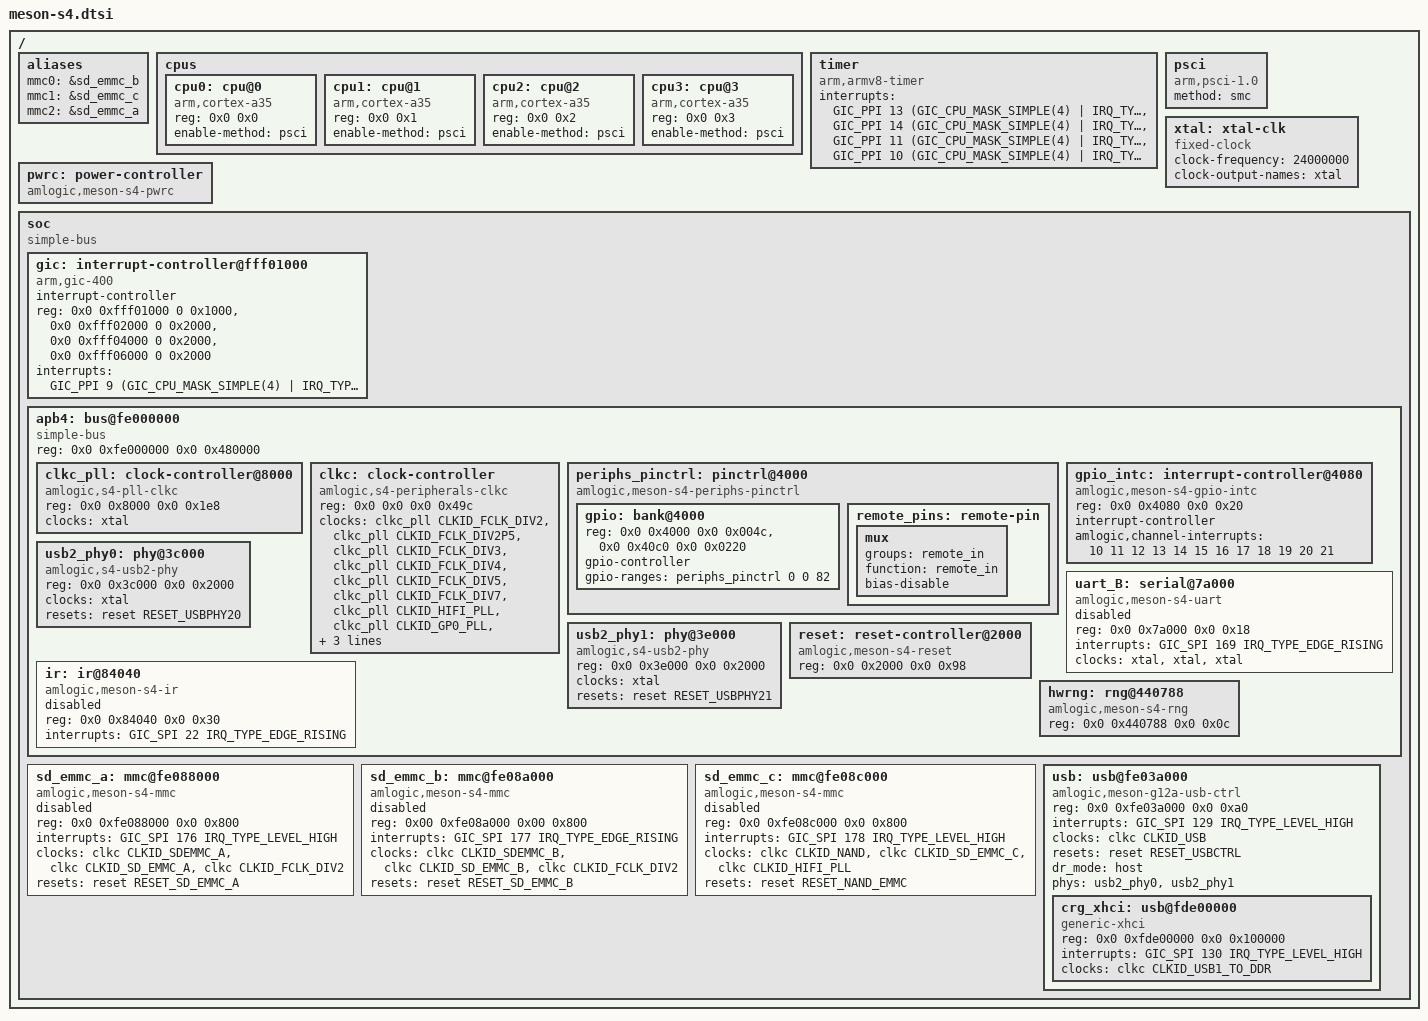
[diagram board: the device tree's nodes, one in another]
// SPDX-License-Identifier: (GPL-2.0+ OR MIT)
/*
 * Copyright (c) 2021 Amlogic, Inc. All rights reserved.
 */
 
#include <dt-bindings/clock/amlogic,s4-peripherals-clkc.h>
#include <dt-bindings/clock/amlogic,s4-pll-clkc.h>
#include <dt-bindings/interrupt-controller/irq.h>
#include <dt-bindings/interrupt-controller/arm-gic.h>
#include <dt-bindings/gpio/gpio.h>
#include <dt-bindings/reset/amlogic,meson-s4-reset.h>

/ {
	
	aliases {
        mmc0 = &sd_emmc_b; /* SD card */
        mmc1 = &sd_emmc_c; /* eMMC */
        mmc2 = &sd_emmc_a; /* SDIO */
    };
	
	cpus {
		#address-cells = <2>;
		#size-cells = <0>;

		cpu0: cpu@0 {
			device_type = "cpu";
			compatible = "arm,cortex-a35";
			reg = <0x0 0x0>;
			enable-method = "psci";
		};

		cpu1: cpu@1 {
			device_type = "cpu";
			compatible = "arm,cortex-a35";
			reg = <0x0 0x1>;
			enable-method = "psci";
		};

		cpu2: cpu@2 {
			device_type = "cpu";
			compatible = "arm,cortex-a35";
			reg = <0x0 0x2>;
			enable-method = "psci";
		};

		cpu3: cpu@3 {
			device_type = "cpu";
			compatible = "arm,cortex-a35";
			reg = <0x0 0x3>;
			enable-method = "psci";
		};
	};

	timer {
		compatible = "arm,armv8-timer";
		interrupts = <GIC_PPI 13 (GIC_CPU_MASK_SIMPLE(4) | IRQ_TYPE_LEVEL_LOW)>,
			     <GIC_PPI 14 (GIC_CPU_MASK_SIMPLE(4) | IRQ_TYPE_LEVEL_LOW)>,
			     <GIC_PPI 11 (GIC_CPU_MASK_SIMPLE(4) | IRQ_TYPE_LEVEL_LOW)>,
			     <GIC_PPI 10 (GIC_CPU_MASK_SIMPLE(4) | IRQ_TYPE_LEVEL_LOW)>;
	};

	psci {
		compatible = "arm,psci-1.0";
		method = "smc";
	};

	xtal: xtal-clk {
		compatible = "fixed-clock";
		clock-frequency = <24000000>;
		clock-output-names = "xtal";
		#clock-cells = <0>;
	};

	pwrc: power-controller {
		compatible = "amlogic,meson-s4-pwrc";
		#power-domain-cells = <1>;
		status = "okay";
	};

	soc {
		compatible = "simple-bus";
		#address-cells = <2>;
		#size-cells = <2>;
		ranges;

		gic: interrupt-controller@fff01000 {
			compatible = "arm,gic-400";
			#interrupt-cells = <3>;
			#address-cells = <0>;
			interrupt-controller;
			reg = <0x0 0xfff01000 0 0x1000>,
			      <0x0 0xfff02000 0 0x2000>,
			      <0x0 0xfff04000 0 0x2000>,
			      <0x0 0xfff06000 0 0x2000>;
			interrupts = <GIC_PPI 9 (GIC_CPU_MASK_SIMPLE(4) | IRQ_TYPE_LEVEL_HIGH)>;
		};

		apb4: bus@fe000000 {
			compatible = "simple-bus";
			reg = <0x0 0xfe000000 0x0 0x480000>;
			#address-cells = <2>;
			#size-cells = <2>;
			ranges = <0x0 0x0 0x0 0xfe000000 0x0 0x480000>;

			clkc_pll: clock-controller@8000 {
				#clock-cells = <1>;
				compatible = "amlogic,s4-pll-clkc";
				reg = <0x0 0x8000 0x0 0x1e8>;
				clocks = <&xtal>;
				clock-names = "xtal";
			};
		
			clkc: clock-controller {
				#clock-cells = <1>;
				compatible = "amlogic,s4-peripherals-clkc";
				reg = <0x0 0x0 0x0 0x49c>;
				clocks = <&clkc_pll CLKID_FCLK_DIV2>,
					<&clkc_pll CLKID_FCLK_DIV2P5>,
					<&clkc_pll CLKID_FCLK_DIV3>,
					<&clkc_pll CLKID_FCLK_DIV4>,
					<&clkc_pll CLKID_FCLK_DIV5>,
					<&clkc_pll CLKID_FCLK_DIV7>,
					<&clkc_pll CLKID_HIFI_PLL>,
					<&clkc_pll CLKID_GP0_PLL>,
					<&clkc_pll CLKID_MPLL0>,
					<&clkc_pll CLKID_MPLL1>,
					<&clkc_pll CLKID_MPLL2>,
					<&clkc_pll CLKID_MPLL3>,
					<&clkc_pll CLKID_HDMI_PLL>,
					<&xtal>;
				clock-names = "fclk_div2", "fclk_div2p5", "fclk_div3",
						"fclk_div4", "fclk_div5", "fclk_div7",
						"hifi_pll", "gp0_pll", "mpll0", "mpll1",
						"mpll2", "mpll3", "hdmi_pll", "xtal";
			};

			periphs_pinctrl: pinctrl@4000 {
				compatible = "amlogic,meson-s4-periphs-pinctrl";
				#address-cells = <2>;
				#size-cells = <2>;
				ranges;

				gpio: bank@4000 {
					reg = <0x0 0x4000 0x0 0x004c>,
					      <0x0 0x40c0 0x0 0x0220>;
					reg-names = "mux", "gpio";
					gpio-controller;
					#gpio-cells = <2>;
					gpio-ranges = <&periphs_pinctrl 0 0 82>;
				};

				remote_pins: remote-pin {
					mux {
						groups = "remote_in";
						function = "remote_in";
						bias-disable;
					};
				};
			};

			gpio_intc: interrupt-controller@4080 {
				compatible = "amlogic,meson-s4-gpio-intc",
					     "amlogic,meson-gpio-intc";
				reg = <0x0 0x4080 0x0 0x20>;
				interrupt-controller;
				#interrupt-cells = <2>;
				amlogic,channel-interrupts =
					<10 11 12 13 14 15 16 17 18 19 20 21>;
			};

			uart_B: serial@7a000 {
				compatible = "amlogic,meson-s4-uart",
					     "amlogic,meson-ao-uart";
				reg = <0x0 0x7a000 0x0 0x18>;
				interrupts = <GIC_SPI 169 IRQ_TYPE_EDGE_RISING>;
				status = "disabled";
				clocks = <&xtal>, <&xtal>, <&xtal>;
				clock-names = "xtal", "pclk", "baud";
			};

			usb2_phy0: phy@3c000 {
				compatible = "amlogic,s4-usb2-phy";
				reg = <0x0 0x3c000 0x0 0x2000>;
				clocks = <&xtal>;
				clock-names = "xtal";
				resets = <&reset RESET_USBPHY20>;
				reset-names = "phy";
				#phy-cells = <0>;
			};

			usb2_phy1: phy@3e000 {
				compatible = "amlogic,s4-usb2-phy";
				reg = <0x0 0x3e000 0x0 0x2000>;
				clocks = <&xtal>;
				clock-names = "xtal";
				resets = <&reset RESET_USBPHY21>;
				reset-names = "phy";
				#phy-cells = <0>;
			};

			reset: reset-controller@2000 {
				compatible = "amlogic,meson-s4-reset";
				reg = <0x0 0x2000 0x0 0x98>;
				#reset-cells = <1>;
			};

			ir: ir@84040 {
				compatible = "amlogic,meson-s4-ir";
				reg = <0x0 0x84040 0x0 0x30>;
				interrupts = <GIC_SPI 22 IRQ_TYPE_EDGE_RISING>;
				status = "disabled";
			};

			hwrng: rng@440788 {
				compatible = "amlogic,meson-s4-rng";
				reg = <0x0 0x440788 0x0 0x0c>;
			};
		};
		
		sd_emmc_a: mmc@fe088000 {
			compatible = "amlogic,meson-s4-mmc";
			reg = <0x0 0xfe088000 0x0 0x800>;
			interrupts = <GIC_SPI 176 IRQ_TYPE_LEVEL_HIGH>;
			clocks = <&clkc CLKID_SDEMMC_A>,
				 <&clkc CLKID_SD_EMMC_A>,
				 <&clkc CLKID_FCLK_DIV2>;
			clock-names = "core", "clkin0", "clkin1";
			resets = <&reset RESET_SD_EMMC_A>;
			status = "disabled";
		};

		sd_emmc_b: mmc@fe08a000 {
			compatible = "amlogic,meson-s4-mmc";
			reg = <0x00 0xfe08a000 0x00 0x800>;
			interrupts = <GIC_SPI 177 IRQ_TYPE_EDGE_RISING>;
			clocks = <&clkc CLKID_SDEMMC_B>,
				 <&clkc CLKID_SD_EMMC_B>,
				 <&clkc CLKID_FCLK_DIV2>;
			clock-names = "core", "clkin0", "clkin1";
			resets = <&reset RESET_SD_EMMC_B>;
			status = "disabled";
		};

		sd_emmc_c: mmc@fe08c000 {
			compatible = "amlogic,meson-s4-mmc";
			reg = <0x0 0xfe08c000 0x0 0x800>;
			interrupts = <GIC_SPI 178 IRQ_TYPE_LEVEL_HIGH>;
			clocks = <&clkc CLKID_NAND>,
				 <&clkc CLKID_SD_EMMC_C>,
				 <&clkc CLKID_HIFI_PLL>;
			clock-names = "core", "clkin0", "clkin1";
			resets = <&reset RESET_NAND_EMMC>;
			status = "disabled";
		};
		
		usb: usb@fe03a000 {
			compatible = "amlogic,meson-g12a-usb-ctrl";
			reg = <0x0 0xfe03a000 0x0 0xa0>;
			interrupts = <GIC_SPI 129 IRQ_TYPE_LEVEL_HIGH>;
			#address-cells = <2>;
			#size-cells = <2>;
			ranges;
			clocks = <&clkc CLKID_USB>;
			resets = <&reset RESET_USBCTRL>;
			dr_mode = "host";
			phys = <&usb2_phy0>, <&usb2_phy1>;
			phy-names = "usb2-phy0", "usb2-phy1";

			crg_xhci: usb@fde00000 {
				compatible = "generic-xhci";
				status = "okay";
				reg = <0x0 0xfde00000 0x0 0x100000>;
				interrupts = <GIC_SPI 130 IRQ_TYPE_LEVEL_HIGH>;
				clocks = <&clkc CLKID_USB1_TO_DDR>;
			};
		};
	};
};
